# myChip register map
Vendor: ARM Ltd.; Series: ARMCM3; File version: 1.2
CPU: CM3 r2p1, little endian, no MPU, no FPU, 3 interrupt priority bits
Registers are 32-bit, read-write, reset 0x0 unless marked. A register's access mark holds for its fields unless they carry their own. Offsets are from the block's base; [hi:lo] are bit positions.

## FLASH
Base 0x40023000
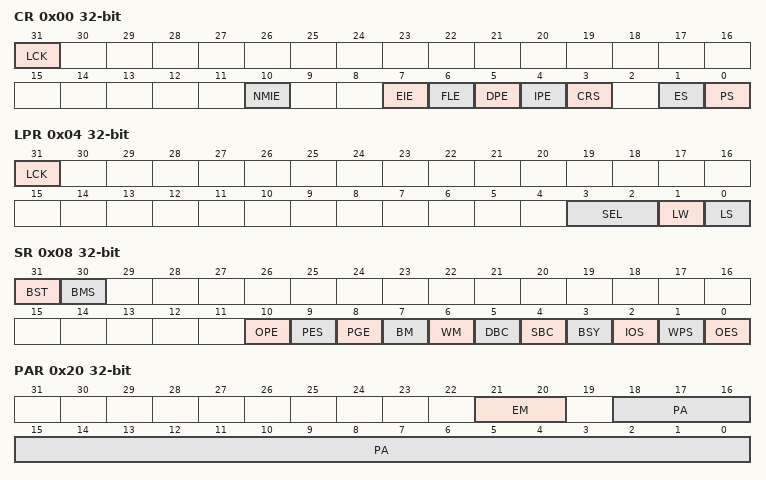
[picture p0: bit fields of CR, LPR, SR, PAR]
0x00 CR — Flash Control Register
  [31] LCK — FLASH解锁标志位(Flash Lock Flag)
  [10] NMIE — FLASH多位ECC异常NMI中断使能(FLASH nBits ECC NMI Enable)
  [7] EIE — FLASH中断使能(Flash Interrupt Enable)
  [6] FLE — FLASH保护更新使能(Flash Launch Enable)
  [5] DPE — FLASH D总线预取使能(Flash Dbus Prefetch Enable)
  [4] IPE — FLASH I总线预取使能(Flash Ibus Prefetch Enable)
  [3] CRS — FLASH缓存刷新控制(Flash Cache Refresh)
  [1] ES — FLASH擦除启动位(Flash Erase Start)
  [0] PS — FLASH编程启动位(Flash Program Start)
0x04 LPR — Flash Lowpower Register
  [31] LCK — FLASH低功耗模式解锁位(Flash Wakeup/Standby Unlock Bit)
  [3:2] SEL — FLASH低功耗BANK选择(Flash Lowpower Bank Selection)
  [1] LW — FLASH低功耗唤醒使能(Flash Lowpower Wakeup)
  [0] LS — FLASH低功耗进入使能(Flash Lowpower Start)
0x08 SR — Flash Status Register
  [31] BST ro — FLASH修改状态标志位(Flash In Busy Status)
  [30] BMS ro — FLASH工作Bank标志位(Flash BankMap Status)
  [10] OPE — FLASH选项字节操作错误状态(Flash OPDR Operation Error Status)
  [9] PES — FLASH擦写操作错误状态(Flash Program/Erase Operation Error Status)
  [8] PGE — FLASH写错误标志位(Flash Program Error Status)
  [7] BM ro — FLASH选项字节Bank标志位(Flash Option BankMap Status)
  [6] WM ro — FLASH工作模式标志位(Flash WorkMode Status)
  [5] DBC — FLASH多个Bit错误标志位(Flash Double Bit Error Pending)
  [4] SBC — FLASH单个Bit错误标志位(Flash Single Bit Error Pending)
  [3] BSY ro — FLASH选项字节修改状态位(Flash OPDR Operation Status)
  [2] IOS — FLASH非法操作错误状态(Flash Illegal Operation Error Status)
  [1] WPS — FLASH写保护错误状态(Flash Write Protect Error Status)
  [0] OES — FLASH操作错误状态(Flash Operation Error Status)
0x10 PDR0 — Flash Data Register0
  [31:0] PD0 — FLASH编程数据(Flash Program Data)
0x14 PDR1 — Flash Data Register1
  [31:0] PD1 — FLASH编程数据(Flash Program Data)
0x20 PAR — Flash Address Register
  [21:20] EM — FLASH擦写模式(Flash Erase Mode)
  [18:0] PA — FLASH编程/擦除地址(Flash Program/Erase Address)
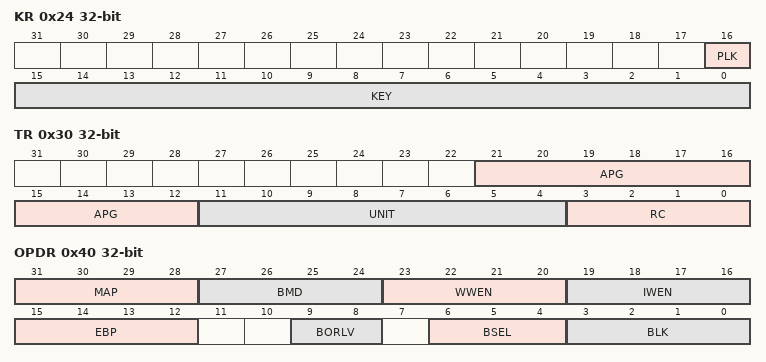
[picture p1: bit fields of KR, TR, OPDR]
0x24 KR — Flash Key Register
  [16] PLK — FLASH读写保护锁(Flash Read/Write Protect Lock)
  [15:0] KEY — FLASH秘钥寄存器(Flash Key Reigster)
0x28 RPR — Flash Read Protect Register
  [7:0] RPLV — FLASH读保护等级设置(Flash Read Protect Level)
0x2C WPR — Flash Write Protect Register
  [31:0] WRPC — FLASH写保护设置(Flash Write Protect Level)
0x30 TR — Flash Timing Register
  [21:12] APG — FLASH编程Timimg设置(Flash Program Cycle Timing)
  [11:4] UNIT — FLASH Us单位(Flash Us Unit Timing)
  [3:0] RC — FLASH读操作Timing设置(Flash Read Cycle Timing)
0x40 OPDR — Flash Option Data Register
  [31:28] MAP — FLASH双Bank Map设置(FLASH BANK Mapping Config)
  [27:24] BMD — FLASH双Bank模式配置(FLASH BANK Mode Config)
  [23:20] WWEN — WWDG默认使能位(WWDG Enable)
  [19:16] IWEN — IWDG默认使能位(IWDG Enable)
  [15:12] EBP — FLASH上电ECC错误控制(FLASH Power On ECC Bypass)
  [9:8] BORLV — BOR电压阈值设置(BOR Voltage Limit Config)
  [6:4] BSEL — BOOT选择配置位(Boot Selection)
  [3:0] BLK — BOOT锁定配置位(Boot Lock Config)
0x50 EAR0 — Flash ECC 1Bit Addr Register
  [31:0] EAD1 ro
0x54 EAR1 — Flash ECC nBit Addr Register
  [31:0] EADn ro

## DMA0
Base 0x40022000
Same registers: DMA1 0x40022020, DMA2 0x40022040, DMA3 0x40022060, DMA4 0x40022080, DMA5 0x400220A0
0x00 SAR — DMA Source Address Register
  [31:0] SAR — DMA传输的源地址（DMA Transfer Source Address）
0x04 DAR — DMA Destination Address Register
  [31:0] DAR — DMA传输的目的地址（DMA Transfer Destination Address）
0x08 DBL — DMA Block Length Register
  [11:0] BL — DMA传输数量长度（DMA Transfer Data Length）
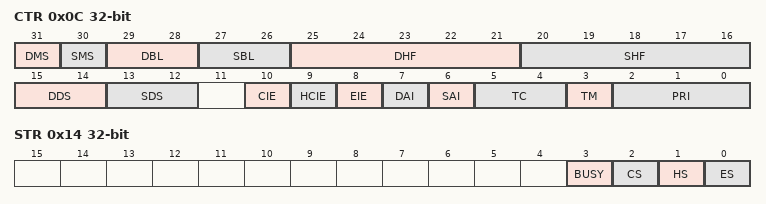
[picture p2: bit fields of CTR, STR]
0x0C CTR — DMA Control Register
  [31] DMS — DMA目的端设备接口控制位（DMA Destination Master Select）
  [30] SMS — DMA源端设备接口控制位（DMA Source Master Select）
  [29:28] DBL — DMA目的端Burst长度设置（DMA Destination Burst Length）
  [27:26] SBL — DMA源端Burst长度设置（DMA Source Burst Length）
  [25:21] DHF — DMA目的端硬件握手接口索引（DMA Destination Handshake Index）
  [20:16] SHF — DMA源端硬件握手接口索引（DMA Source Handshake Index）
  [15:14] DDS — DMA目的端传输位宽选择（DMA Destination Data Width Select）
  [13:12] SDS — DMA源端传输位宽选择（DMA Source Data Width Select）
  [10] CIE — DMA传输完成中断使能位（DMA Transfer Complete Interrupt Enable）
  [9] HCIE — DMA传输一半完成中断使能位（DMA Transfer half Completed Interrupt Enable）
  [8] EIE — DMA错误中断使能位（DMA Error Interrupt Enable）
  [7] DAI — DMA目的端地址控制位（DMA Destination Address Control）
  [6] SAI — DMA源端地址控制位（DMA Source Address Control）
  [5:4] TC — DMA传输类型控制（DMA Transfer Type Control）
  [3] TM — DMA传输模式控制（DMA Transfer Mode Control）
  [2:0] PRI — DMA通道优先级设置（DMA Channel Priority Control）(根据通道数目)
0x10 CER — DMA Channel Enable Register
  [0] CEN — DMA传输使能（DMA Enable）
0x14 STR — DMA Status Register
  [3] BUSY ro — DMA传输状态标志位（DMA Transfer Status）
  [2] CS — DMA传输完成中断状态位（DMA Transfer Completed Interrupt Status）
  [1] HS — DMA传输一半完成中断状态位（DMA Transfer Half Completed Interrupt Status）
  [0] ES — DMA错误中断状态位（DMA Error Interrupt Status）
0x18 DTL — DMA Transfer Length Register
  [31:0] DTR — DMA数据传输长度地址（DMA Transfer Length Register）
